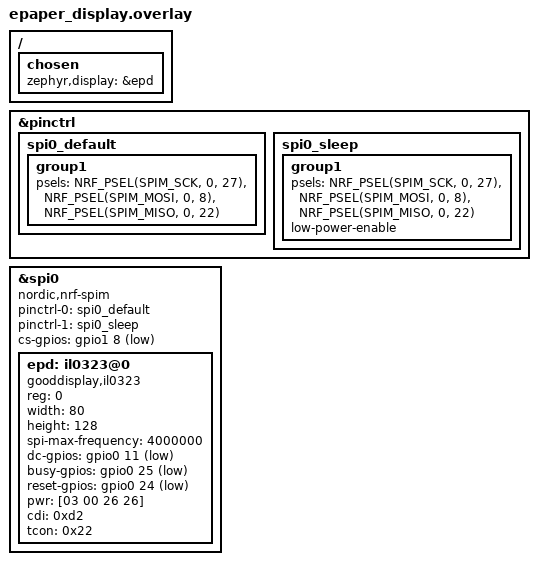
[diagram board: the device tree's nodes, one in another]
/*
 * Copyright (c) 2022 The ZMK Contributors
 *
 * SPDX-License-Identifier: MIT
 */

/{
    chosen {
        zephyr,display = &epd;
       
    };
};
   
&pinctrl {
    spi0_default: spi0_default {
        group1 {
            psels = <NRF_PSEL(SPIM_SCK, 0, 27)>,
                <NRF_PSEL(SPIM_MOSI, 0, 8)>,
                <NRF_PSEL(SPIM_MISO, 0, 22)>;
        };
    };

    spi0_sleep: spi0_sleep {
        group1 {
            psels = <NRF_PSEL(SPIM_SCK, 0, 27)>,
                <NRF_PSEL(SPIM_MOSI, 0, 8)>,
                <NRF_PSEL(SPIM_MISO, 0, 22)>;
            low-power-enable;
        };
    };
};

&spi0 {
    status = "okay";
    compatible = "nordic,nrf-spim";
    pinctrl-0 = <&spi0_default>;
    pinctrl-1 = <&spi0_sleep>;
    pinctrl-names = "default", "sleep";
    cs-gpios = <&gpio1 8 GPIO_ACTIVE_LOW>;

    epd: il0323@0 {
        compatible = "gooddisplay,il0323";
        reg =  <0>;
        width = <80>;
        height = <128>;
        spi-max-frequency = <4000000>;
        dc-gpios = <&gpio0 11 GPIO_ACTIVE_LOW>;
        busy-gpios = <&gpio0 25 GPIO_ACTIVE_LOW>;
        reset-gpios = <&gpio0 24 GPIO_ACTIVE_LOW>;
        pwr = [03 00 26 26];
        cdi = <0xd2>;
        tcon = <0x22>;
    };
};
